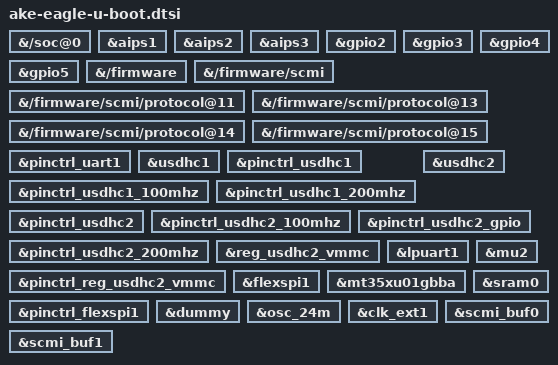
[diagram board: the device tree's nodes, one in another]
// SPDX-License-Identifier: GPL-2.0+
/*
 * Copyright 2026 Akkodis Edge
 */

&{/soc@0} {
	bootph-pre-ram;
};

&aips1 {
	bootph-pre-ram;
};

&aips2 {
	bootph-pre-ram;
};

&aips3 {
	bootph-pre-ram;
};

&gpio2 {
	bootph-pre-ram;
};

&gpio3 {
	bootph-pre-ram;
};

&gpio4 {
	bootph-pre-ram;
};

&gpio5 {
	bootph-pre-ram;
};

&{/firmware} {
	bootph-pre-ram;
};

&{/firmware/scmi} {
	bootph-pre-ram;
};

&{/firmware/scmi/protocol@11} {
	bootph-pre-ram;
};

&{/firmware/scmi/protocol@13} {
	bootph-pre-ram;
};

&{/firmware/scmi/protocol@14} {
	bootph-pre-ram;
};

&{/firmware/scmi/protocol@15} {
	bootph-pre-ram;
};

&pinctrl_uart1 {
	bootph-pre-ram;
};

&usdhc1 {
	bootph-pre-ram;
};

&pinctrl_usdhc1 {
	bootph-pre-ram;
};

&pinctrl_usdhc1_100mhz {
	bootph-pre-ram;
};

&pinctrl_usdhc1_200mhz {
	bootph-pre-ram;
};

&usdhc2 {
	bootph-pre-ram;
};

&pinctrl_usdhc2 {
	bootph-pre-ram;
};

&pinctrl_usdhc2_100mhz {
	bootph-pre-ram;
};

&pinctrl_usdhc2_200mhz {
	bootph-pre-ram;
};

&pinctrl_usdhc2_gpio {
	bootph-pre-ram;
};

&reg_usdhc2_vmmc {
	bootph-pre-ram;
};

&pinctrl_reg_usdhc2_vmmc {
	bootph-pre-ram;
};

&lpuart1 {
	bootph-pre-ram;
};

&flexspi1 {
	bootph-pre-ram;
};

&mt35xu01gbba {
	bootph-pre-ram;
};

&pinctrl_flexspi1 {
	bootph-pre-ram;
};

&mu2 {
	bootph-pre-ram;
};

&dummy {
	bootph-pre-ram;
};

&osc_24m {
	bootph-pre-ram;
};

&clk_ext1 {
	bootph-pre-ram;
};

&sram0 {
	bootph-pre-ram;
};

&scmi_buf0 {
	bootph-pre-ram;
};

&scmi_buf1 {
	bootph-pre-ram;
};


